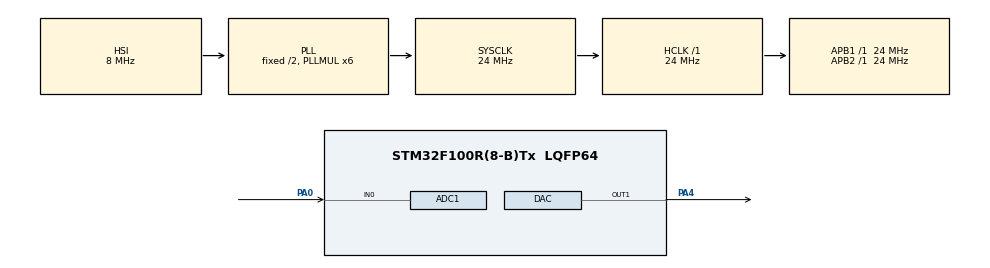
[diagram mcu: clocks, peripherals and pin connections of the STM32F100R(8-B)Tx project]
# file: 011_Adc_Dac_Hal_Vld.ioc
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ADC1.Channel-0\#ChannelRegularConversion=ADC_CHANNEL_0
ADC1.NbrOfConversionFlag=1
ADC1.Rank-0\#ChannelRegularConversion=1
ADC1.SamplingTime-0\#ChannelRegularConversion=ADC_SAMPLETIME_71CYCLES_5
ADC1.master=1
Mcu.Family=STM32F1
Mcu.Name=STM32F100R(8-B)Tx
Mcu.Package=LQFP64
NVIC.PriorityGroup=NVIC_PRIORITYGROUP_4
PA0-WKUP.Signal=ADCx_IN0
PA13.Mode=Serial_Wire
PA13.Signal=SYS_JTMS-SWDIO
PA14.Mode=Serial_Wire
PA14.Signal=SYS_JTCK-SWCLK
PA4.Signal=COMP_DAC1_group
ProjectManager.HeapSize=0x200
ProjectManager.StackSize=0x400
ProjectManager.TargetToolchain=STM32CubeIDE
RCC.AHBFreq_Value=24000000
RCC.APB1Freq_Value=24000000
RCC.APB1TimFreq_Value=24000000
RCC.APB2Freq_Value=24000000
RCC.APB2TimFreq_Value=24000000
RCC.HCLKFreq_Value=24000000
RCC.PLLMUL=RCC_PLL_MUL6
RCC.SYSCLKFreq_VALUE=24000000
RCC.SYSCLKSource=RCC_SYSCLKSOURCE_PLLCLK
SH.ADCx_IN0.0=ADC1_IN0,IN0
SH.COMP_DAC1_group.0=DAC_OUT1,DAC_OUT1
board=custom

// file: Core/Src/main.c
/* USER CODE BEGIN Header */
/**
  ******************************************************************************
  * @file           : main.c
  * @brief          : Main program body
  ******************************************************************************
  * @attention
  *
  * Copyright (c) 2024 STMicroelectronics.
  * All rights reserved.
  *
  * This software is licensed under terms that can be found in the LICENSE file
  * in the root directory of this software component.
  * If no LICENSE file comes with this software, it is provided AS-IS.
  *
  ******************************************************************************
  */
/* USER CODE END Header */
#include "main.h"

ADC_HandleTypeDef hadc1;

DAC_HandleTypeDef hdac;

uint16_t adc_value, dac_value;

void SystemClock_Config(void);
static void MX_GPIO_Init(void);
static void MX_ADC1_Init(void);
static void MX_DAC_Init(void);
uint16_t Read_Adc(void);

int main(void)
{

  /* MCU Configuration--------------------------------------------------------*/

  /* Reset of all peripherals, Initializes the Flash interface and the Systick. */
  HAL_Init();

  /* Configure the system clock */
  SystemClock_Config();

  /* Initialize all configured peripherals */
  MX_GPIO_Init();
  MX_ADC1_Init();
  MX_DAC_Init();
  /* USER CODE BEGIN 2 */
  HAL_DAC_Start(&hdac, DAC_CHANNEL_1);

  /* USER CODE END 2 */

  /* Infinite loop */
  while (1)
  {

    /* USER CODE BEGIN 3 */
	  dac_value = Read_Adc();
	  HAL_DAC_SetValue(&hdac, DAC_CHANNEL_1, DAC_ALIGN_12B_R, dac_value);
  }
  /* USER CODE END 3 */
}

/**
 * @brief ADC READ FUNCTION
 * @RETVAL None
 * @PARAM None
 */
uint16_t  Read_Adc(void){

	HAL_ADC_Start(&hadc1);

	if(HAL_ADC_PollForConversion(&hadc1, 1000) == HAL_OK){
		adc_value = HAL_ADC_GetValue(&hadc1);
	}

	HAL_ADC_Stop(&hadc1);

	return adc_value;
}

void SystemClock_Config(void)
{
  RCC_OscInitTypeDef RCC_OscInitStruct = {0};
  RCC_ClkInitTypeDef RCC_ClkInitStruct = {0};
  RCC_PeriphCLKInitTypeDef PeriphClkInit = {0};

  /** Initializes the RCC Oscillators according to the specified parameters
  * in the RCC_OscInitTypeDef structure.
  */
  RCC_OscInitStruct.OscillatorType = RCC_OSCILLATORTYPE_HSI;
  RCC_OscInitStruct.HSIState = RCC_HSI_ON;
  RCC_OscInitStruct.HSICalibrationValue = RCC_HSICALIBRATION_DEFAULT;
  RCC_OscInitStruct.PLL.PLLState = RCC_PLL_ON;
  RCC_OscInitStruct.PLL.PLLSource = RCC_PLLSOURCE_HSI_DIV2;
  RCC_OscInitStruct.PLL.PLLMUL = RCC_PLL_MUL6;
  if (HAL_RCC_OscConfig(&RCC_OscInitStruct) != HAL_OK)
  {
    Error_Handler();
  }

  /** Initializes the CPU, AHB and APB buses clocks
  */
  RCC_ClkInitStruct.ClockType = RCC_CLOCKTYPE_HCLK|RCC_CLOCKTYPE_SYSCLK
                              |RCC_CLOCKTYPE_PCLK1|RCC_CLOCKTYPE_PCLK2;
  RCC_ClkInitStruct.SYSCLKSource = RCC_SYSCLKSOURCE_PLLCLK;
  RCC_ClkInitStruct.AHBCLKDivider = RCC_SYSCLK_DIV1;
  RCC_ClkInitStruct.APB1CLKDivider = RCC_HCLK_DIV1;
  RCC_ClkInitStruct.APB2CLKDivider = RCC_HCLK_DIV1;

  if (HAL_RCC_ClockConfig(&RCC_ClkInitStruct, FLASH_LATENCY_0) != HAL_OK)
  {
    Error_Handler();
  }
  PeriphClkInit.PeriphClockSelection = RCC_PERIPHCLK_ADC;
  PeriphClkInit.AdcClockSelection = RCC_ADCPCLK2_DIV2;
  if (HAL_RCCEx_PeriphCLKConfig(&PeriphClkInit) != HAL_OK)
  {
    Error_Handler();
  }
}

static void MX_ADC1_Init(void)
{

  ADC_ChannelConfTypeDef sConfig = {0};

  /** Common config
  */
  hadc1.Instance = ADC1;
  hadc1.Init.ScanConvMode = ADC_SCAN_DISABLE;
  hadc1.Init.ContinuousConvMode = DISABLE;
  hadc1.Init.DiscontinuousConvMode = DISABLE;
  hadc1.Init.ExternalTrigConv = ADC_SOFTWARE_START;
  hadc1.Init.DataAlign = ADC_DATAALIGN_RIGHT;
  hadc1.Init.NbrOfConversion = 1;
  if (HAL_ADC_Init(&hadc1) != HAL_OK)
  {
    Error_Handler();
  }

  /** Configure Regular Channel
  */
  sConfig.Channel = ADC_CHANNEL_0;
  sConfig.Rank = ADC_REGULAR_RANK_1;
  sConfig.SamplingTime = ADC_SAMPLETIME_71CYCLES_5;
  if (HAL_ADC_ConfigChannel(&hadc1, &sConfig) != HAL_OK)
  {
    Error_Handler();
  }

}

static void MX_DAC_Init(void)
{

  DAC_ChannelConfTypeDef sConfig = {0};

  /** DAC Initialization
  */
  hdac.Instance = DAC;
  if (HAL_DAC_Init(&hdac) != HAL_OK)
  {
    Error_Handler();
  }

  /** DAC channel OUT1 config
  */
  sConfig.DAC_Trigger = DAC_TRIGGER_NONE;
  sConfig.DAC_OutputBuffer = DAC_OUTPUTBUFFER_ENABLE;
  if (HAL_DAC_ConfigChannel(&hdac, &sConfig, DAC_CHANNEL_1) != HAL_OK)
  {
    Error_Handler();
  }

}

static void MX_GPIO_Init(void)
{

  /* GPIO Ports Clock Enable */
  __HAL_RCC_GPIOA_CLK_ENABLE();

}

void Error_Handler(void)
{
  __disable_irq();
  while (1)
  {
  }
}
